# STC32G144K246 register map
Vendor: STC; File version: 2.0
Registers are 8-bit, read-write, no defined reset value unless marked. A register's access mark holds for its fields unless they carry their own. Offsets are from the block's base; [hi:lo] are bit positions; {n}, {i} and the like mark numbered series; 'fields as' and 'values as' point back to an identical list.

## PWMA — 高级 PWM A：使能、状态、计数、周期和输出
Base 0x007EF940
0x00 PWMA_CCR5H — PWMA捕获比较寄存器5
  [7:0] CCRA5 — 捕获/比较5 的16 位值（n=A/C/E） CCRn5 包含了装入当前比较值（预装载值）。如果在PWMn_CCMR5 寄存器（OCn5PE 位）中未选 择预装载功能，写入的数值会立即传输至当前寄存器中。否则只有当更新事件发生时，此预装载 值才传输至当前捕获/比较5 寄存器中。当前比较值同计数器PW
0x01 PWMA_CCR5L — PWMA捕获比较寄存器5
  fields as PWMA_CCR5H
0x03 PWMA_CCR6H — PWMA捕获比较寄存器6
  [7:0] CCRA6 — 捕获/比较n 的16 位值（n=A/C/E） CCRn6 包含了装入当前比较值（预装载值）。如果在PWMn_CCMR6 寄存器（OCn6PE 位）中未选 择预装载功能，写入的数值会立即传输至当前寄存器中。否则只有当更新事件发生时，此预装载 值才传输至当前捕获/比较6 寄存器中。当前比较值同计数器PW
0x04 PWMA_CCR6L — PWMA捕获比较寄存器6
  fields as PWMA_CCR6H
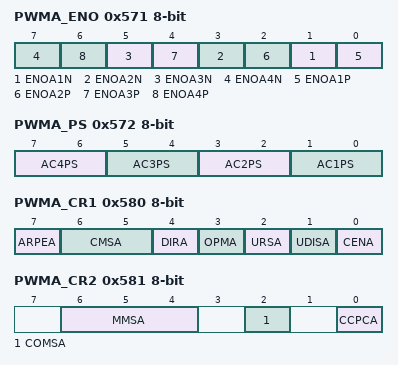
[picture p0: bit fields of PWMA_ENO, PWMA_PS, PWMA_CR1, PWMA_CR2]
0x571 PWMA_ENO — PWMA输出使能控制
  [2n-1] ENOA{n}N (n=1..4) — 尚未自动匹配到此字段的独立说明；请查看下方章节说明。
  [2n-2] ENOA{n}P (n=1..4) — 尚未自动匹配到此字段的独立说明；请查看下方章节说明。
0x572 PWMA_PS — PWMA输出脚选择寄存器
  [7:6] AC4PS — 高级PWMA 通道4 输出脚选择位
    0=PWMA4P：P1.6；PWMA4N：P1.7; 1=PWMA4P：P2.6；PWMA4N：P2.7; 2=PWMA4P：P6.6；PWMA4N：P6.7; 3=PWMA4P：P3.4；PWMA4N：P3.3
  [5:4] AC3PS — 高级PWMA 通道3 输出脚选择位
    0=PWMA3P：P1.4；PWM3AN：P1.5; 1=PWMA3P：P2.4；PWM3AN：P2.5; 2=PWMA3P：P6.4；PWM3AN：P6.5; 3=PWMA3P：-；PWM3AN：-
  [3:2] AC2PS — 高级PWMA 通道2 输出脚选择位
    0=PWMA2P：P1.2；PWMA2N：P1.3; 1=PWMA2P：P2.2；PWMA2N：P2.3; 2=PWMA2P：P6.2；PWMA2N：P6.3; 3=PWMA2P：-；PWMA2N：-
  [1:0] AC1PS — 高级PWMA 通道1 输出脚选择位
    0=PWMA1P：P1.0；PWMA1N：P1.1; 1=PWMA1P：P2.0；PWMA1N：P2.1; 2=PWMA1P：P6.0；PWMA1N：P6.1; 3=PWMA1P：-；PWMA1N：-
0x580 PWMA_CR1 — PWMA控制寄存器1
  [7] ARPEA — 自动预装载允许位（n=A/B/C/D/E/F）
    0=PWMn_ARR 寄存器没有缓冲，它可以被直接写入; 1=PWMn_ARR 寄存器由预装载缓冲器缓冲
  [6:5] CMSA — 选择对齐模式（n=A/B/C/D/E/F）
    0=对齐模式：边沿对齐模式；说明：计数器依据方向位（DIR）向上或向下计数; 1=对齐模式：中央对齐模式1；说明：计数器交替地向上和向下计数。配置为输出的通道的输出比较中断标志位(CCnIF)只在计数器向下计数时被置1。; 2=对齐模式：中央对齐模式2；说明：计数器交替地向上和向下计数。配置为输出的通道的输出比较中断标志位(CCnIF)只在计数器向上计数时被置1。; 3=对齐模式：中央对齐模式3；说明：计数器交替地向上和向下计数。配置为输出的通道的输出比较中断标志位(CCnIF)在计数器向上和向下计数时均被置1。
  [4] DIRA — 计数器的计数方向（n=A/B/C/D/E/F）
    0=计数器向上计数；; 1=计数器向下计数。
  [3] OPMA — 单脉冲模式（n=A/B/C/D/E/F）
    0=在发生更新事件时，计数器不停止；; 1=在发生下一次更新事件时，清除CEN 位，计数器停止。
  [2] URSA — 更新请求源（n=A/B/C/D/E/F）
    0=如果UDIS 允许产生更新事件，则下述任一事件产生一个更新中断：; 1=如果UDIS 允许产生更新事件，则只有当下列事件发生时才产生更新中断，并UIF 置1：
  [1] UDISA — 禁止更新（n=A/B/C/D/E/F）
    0=一旦下列事件发生，产生更新（UEV）事件：; 1=不产生更新事件，影子寄存器（ARR、PSC、CCRx）保持它们的值。如果设置了UG 位或时钟/
  [0] CENA — 允许计数器（n=A/B/C/D/E/F）
    0=禁止计数器；; 1=使能计数器。
0x581 PWMA_CR2 — PWMA控制寄存器2
  [6:4] MMSA — 主模式选择（n=A/C/E）
    0=主模式：复位；说明：PWMn_EGR寄存器的UG位被用于作为触发输出（TRGO）。如果触发输入（时钟/触发控制器配置为复位模式）产生复位，则TRGO上的信号相对实际的复位会有一个延迟; 1=主模式：使能；说明：计数器使能信号被用于作为触发输出（TRGO）。其用于启动多个PWM，以便控制在一段时间内使能从PWM。计数器使能信号是通过CEN控制位和门控模式下的触发输入信号的逻辑或产生。除非选择了主/从模式，当计数器使能信号受控于触发输入时，TRGO上会有一个延迟。; 2=主模式：更新；说明：更新事件被选为触发输出（TRGO）; 3=主模式：比较脉冲；说明：一旦发生一次捕获或一次比较成功，当CCn5IF标志被置1时，触发输出送出一个正脉冲（TRGO）; {v}=主模式：比较；说明：OCn{v+1}REF信号被用于作为触发输出（TRGO） (v=4..7)
  [2] COMSA — 捕获/比较控制位的更新控制选择（n=A/B/C/D/E/F）
    0=当CCPCn=1 时，只有在COMG 位置1 的时候这些控制位才被更新; 1=当CCPCn=1 时，只有在COMG 位置1 或TRGI 发生上升沿的时候这些控制位才被更新
  [0] CCPCA — 捕获/比较预装载控制位（n=A/B/C/D/E/F）
    0=CCIE，CCINE，CCiP，CCiNP 和OCIM 位不是预装载的; 1=CCIE，CCINE，CCiP，CCiNP 和OCIM 位是预装载的；设置该位后，它们只在设置了COMG 位
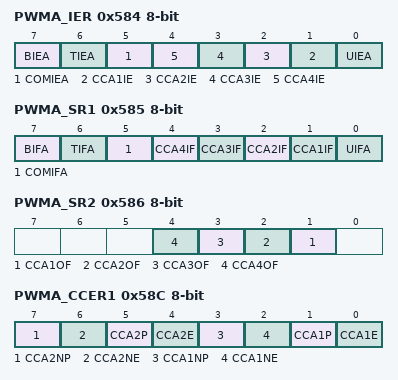
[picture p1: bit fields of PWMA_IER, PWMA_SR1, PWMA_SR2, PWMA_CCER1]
0x584 PWMA_IER — PWMA中断使能寄存器
  [7] BIEA — 允许刹车中断（n=A/B/C/D/E/F）
    0=禁止刹车中断；; 1=允许刹车中断。
  [6] TIEA — 触发中断使能（n=A/B/C/D/E/F）
    0=禁止触发中断；; 1=使能触发中断。
  [5] COMIEA — 尚未自动匹配到此字段的独立说明；请查看下方章节说明。
  [n] CCA{n}IE (n=1..4) — 允许捕获/比较n 中断（n=A/B/C/D/E/F，x=1/2/3/4/5/6/7/8）
    0=禁止捕获/比较n 中断；; 1=允许捕获/比较n 中断。
  [0] UIEA — 允许更新中断（n=A/B/C/D/E/F）
    0=禁止更新中断；; 1=允许更新中断。
0x585 PWMA_SR1 ro — PWMA状态寄存器1
  [7] BIFA — 刹车中断标记。一旦刹车输入有效，由硬件对该位置1。 如果刹车输入无效，则该位可由软件清0。（n=A/B/C/D/E/F）
    0=无刹车事件产生; 1=刹车输入上检测到有效电平
  [6] TIFA — 触发器中断标记。当发生触发事件时由硬件对该位置1。由软件清0。（n=A/B/C/D/E/F）
    0=无触发器事件产生; 1=触发中断等待响应
  [5] COMIFA — PWMn比较中断请求标志。需要软件清零。（n=A/B/C/D/E/F）
  [n] CCA{n}IF (n=1..4) — 捕获/比较nx中断标记，参考CC1IF描述（n=A/B/C/D/E/F，x=1/2/3/4/5/6/7/8）
  [0] UIFA — PWMn更新中断请求标志。需要软件清零。（n=A/B/C/D/E/F）
0x586 PWMA_SR2 ro — PWMA状态寄存器2
  [n] CCA{n}OF (n=1..4) — 捕获/比较nx重复捕获标记。参见CC1OF描述。（n=A/B/C/D/E/F，x=1/2/3/4/5/6/7/8）
0x58C PWMA_CCER1 — PWMA捕获比较使能寄存器1
  [7] CCA2NP — OCnN（OCn 通道负极）比较输出极性。参考CCA1NP（n=A/B/C/D/E/F，x=1/2/5/6）
  [6] CCA2NE — OCnN（OCn 通道负极）比较输出使能。参考CCA1NE（n=A/B/C/D/E/F，x=1/2/5/6）
  [5] CCA2P — OCn 输入捕获/比较输出极性。参考CCA1P（n=A/B/C/D/E/F，x=1/2/5/6）
  [4] CCA2E — OCn 输入捕获/比较输出使能。参考CCA1E（n=A/B/C/D/E/F，x=1/2/5/6）
  [3] CCA1NP — OCnN（OCn 通道负极）比较输出极性。参考CCA1NP（n=A/B/C/D/E/F，x=1/2/5/6）
  [2] CCA1NE — OCnN（OCn 通道负极）比较输出使能。参考CCA1NE（n=A/B/C/D/E/F，x=1/2/5/6）
  [1] CCA1P — OCn 输入捕获/比较输出极性。参考CCA1P（n=A/B/C/D/E/F，x=1/2/5/6）
  [0] CCA1E — OCn 输入捕获/比较输出使能。参考CCA1E（n=A/B/C/D/E/F，x=1/2/5/6）
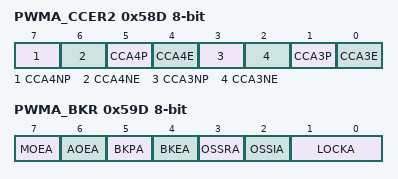
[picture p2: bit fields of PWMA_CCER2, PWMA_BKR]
0x58D PWMA_CCER2 — PWMA捕获比较使能寄存器2
  [7] CCA4NP — OCnN（OCn 通道负极）比较输出极性。参考CCA1NP（n=A/B/C/D/E/F，x=3/4/7/8）
  [6] CCA4NE — OCnN（OCn 通道负极）比较输出使能。参考CCA1NE（n=A/B/C/D/E/F，x=3/4/7/8）
  [5] CCA4P — OCn 输入捕获/比较输出极性。参考CCA1P（n=A/B/C/D/E/F，x=3/4/7/8）
  [4] CCA4E — OCn 输入捕获/比较输出使能。参考CCA1E（n=A/B/C/D/E/F，x=3/4/7/8）
  [3] CCA3NP — OCnN（OCn 通道负极）比较输出极性。参考CCA1NP（n=A/B/C/D/E/F，x=3/4/7/8）
  [2] CCA3NE — OCnN（OCn 通道负极）比较输出使能。参考CCA1NE（n=A/B/C/D/E/F，x=3/4/7/8）
  [1] CCA3P — OCn 输入捕获/比较输出极性。参考CCA1P（n=A/B/C/D/E/F，x=3/4/7/8）
  [0] CCA3E — OCn 输入捕获/比较输出使能。参考CCA1E（n=A/B/C/D/E/F，x=3/4/7/8）
0x58E PWMA_CNTRH ro — PWMA计数器高字节
  [7:0] CNTA — 计数器的16 位值（n=A/B/C/D/E/F）
0x58F PWMA_CNTRL ro — PWMA计数器低字节
  [7:0] CNTA — 计数器的16 位值（n=A/B/C/D/E/F）
0x590 PWMA_PSCRH — PWMA预分频高字节
  [7:0] PSC — 尚未自动匹配到此字段的独立说明；请查看下方章节说明。
0x591 PWMA_PSCRL — PWMA预分频低字节
  [7:0] PSCA — 预分频器的16 位值。（n=A/B/C/D/E/F） 预分频器用于对CK_PSC进行分频。计数器的时钟频率（fCK_CNT）等于fCK_PSC（/ PSCR[15:0]+1）。 PSCR 包含了当更新事件产生时装入当前预分频器寄存器的值（更新事件包括计数器被TIM_EGR 的UG 位清0 或被工作在
0x592 PWMA_ARRH — PWMA自动重装寄存器高字节
  [7:0] ARRA — 自动重装载16 位值（n=A/B/C/D/E/F） ARR 包含了将要装载入实际的自动重装载寄存器的值。当自动重装载的值为0 时，计数器不工作。
0x593 PWMA_ARRL — PWMA自动重装寄存器低字节
  fields as PWMA_ARRH
0x595 PWMA_CCR1H — PWMA比较捕获寄存器1高位
  [7:0] CCRA1 — 捕获/比较n 的16 值（n=A/B/C/D/E/F，x=1/5） 若CCn 通道配置为输出：CCRn 包含了装入当前比较值（预装载值）。如果在PWMn_CCMR1 寄存 器（OCnPE 位）中未选择预装载功能，写入的数值会立即传输至当前寄存器中。否则只有当更新 事件发生时，此预装载值才传输至当前捕
0x596 PWMA_CCR1L — PWMA比较捕获寄存器1低位
  fields as PWMA_CCR1H
{0x593+2i} PWMA_CCR{i}H (i=2..4) — PWMA比较捕获寄存器{i}高位
  [7:0] CCRA{i} — 捕获/比较n 的16 位值（n=A/B/C/D/E/F，x={i}/{i+4}）
{0x594+2i} PWMA_CCR{i}L (i=2..4) — PWMA比较捕获寄存器{i}低位
  [7:0] CCRA{i} — 捕获/比较n 的16 位值（n=A/B/C/D/E/F，x={i}/{i+4}）
0x59D PWMA_BKR ro — PWMA刹车寄存器
  [7] MOEA — 主输出使能。一旦刹车输入有效，该位被硬件异步清0。根据AOE 位的设置值，该位可以由软 件置1 或被自动置1。它仅对配置为输出的通道有效。（n=A/B/C/D/E/F）
    0=禁止OC 和OCN 输出或强制为空闲状态; 1=如果设置了相应的使能位（PWMn_CCERX 寄存器的CCIE 位），则使能OC 和OCN 输出。
  [6] AOEA — 自动输出使能（n=A/B/C/D/E/F）
    0=MOE 只能被软件置1；; 1=MOE 能被软件置1 或在下一个更新事件被自动置1（如果刹车输入无效）。
  [5] BKPA — 刹车输入极性（n=A/B/C/D/E/F）
    0=刹车输入低电平有效; 1=刹车输入高电平有效
  [4] BKEA — 刹车功能使能（n=A/B/C/D/E/F）
    0=禁止刹车输入（BRK）; 1=开启刹车输入（BRK）
  [3] OSSRA — 运行模式下“关闭状态”选择。该位在MOE=1 且通道设为输出时有效（n=A/B/C/D/E/F）
    0=当PWM 不工作时，禁止OC/OCN 输出（OC/OCN 使能输出信号=0）；; 1=当 PWM 不工作时，一旦 CCiE=1 或 CCiNE=1，首先开启 OC/OCN 并输出无效电平，然后置
  [2] OSSIA — 空闲模式下“关闭状态”选择。该位在MOE=0 且通道设为输出时有效。（n=A/B/C/D/E/F）
    0=当PWM 不工作时，禁止OC/OCN 输出（OC/OCN 使能输出信号=0）；; 1=当PWM 不工作时，一旦CCiE=1 或CCiNE=1，OC/OCN 首先输出其空闲电平，然后 OC/OCN
  [1:0] LOCKA — 锁定设置。该位为防止软件错误而提供的写保护措施（n=A/B/C/D/E/F）
    0=保护级别：无保护；保护内容：寄存器无写保护; 1=保护级别：锁定级别1；保护内容：不能写入PWMn_BKR寄存器的MOE、BKE、BKP、AOE位和PWMn_OISR寄存器的OISI位; 2=保护级别：锁定级别2；保护内容：不能写入锁定级别1中的各位，也不能写入CC极性位以及OSSR/OSSI位; 3=保护级别：锁定级别3；保护内容：不能写入锁定级别2中的各位，也不能写入CC控制位
